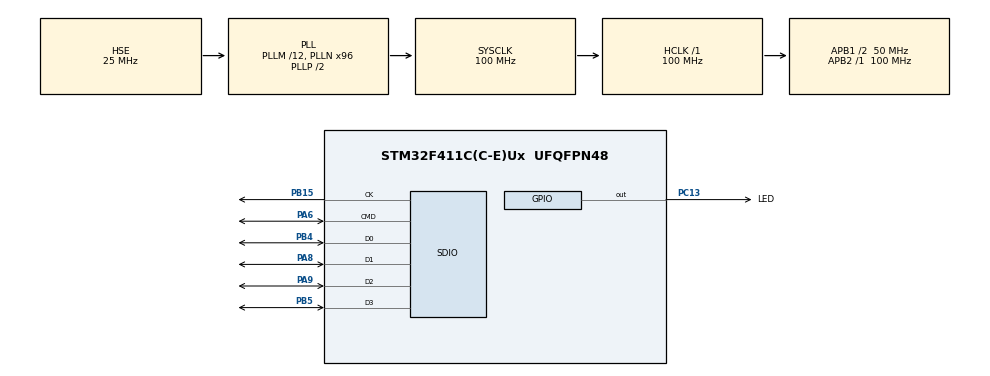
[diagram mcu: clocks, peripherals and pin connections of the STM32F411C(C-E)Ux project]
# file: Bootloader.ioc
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FATFS._MAX_SS=4096
Mcu.Family=STM32F4
Mcu.Name=STM32F411C(C-E)Ux
Mcu.Package=UFQFPN48
NVIC.PriorityGroup=NVIC_PRIORITYGROUP_4
PA13.Mode=Trace_Asynchronous_SW
PA13.Signal=SYS_JTMS-SWDIO
PA14.Mode=Trace_Asynchronous_SW
PA14.Signal=SYS_JTCK-SWCLK
PA6.GPIO_PuPd=GPIO_PULLUP
PA6.Mode=SD_4_bits_Wide_bus
PA6.Signal=SDIO_CMD
PA8.GPIO_PuPd=GPIO_PULLUP
PA8.Mode=SD_4_bits_Wide_bus
PA8.Signal=SDIO_D1
PA9.GPIO_PuPd=GPIO_PULLUP
PA9.Mode=SD_4_bits_Wide_bus
PA9.Signal=SDIO_D2
PB15.GPIO_PuPd=GPIO_NOPULL
PB15.Mode=SD_4_bits_Wide_bus
PB15.Signal=SDIO_CK
PB3.Mode=Trace_Asynchronous_SW
PB3.Signal=SYS_JTDO-SWO
PB4.GPIO_PuPd=GPIO_PULLUP
PB4.Mode=SD_4_bits_Wide_bus
PB4.Signal=SDIO_D0
PB5.GPIO_PuPd=GPIO_PULLUP
PB5.Mode=SD_4_bits_Wide_bus
PB5.Signal=SDIO_D3
PC13-ANTI_TAMP.GPIO_Label=LED
PC13-ANTI_TAMP.PinState=GPIO_PIN_SET
PC13-ANTI_TAMP.Signal=GPIO_Output
PH0\ -\ OSC_IN.Mode=HSE-External-Oscillator
PH0\ -\ OSC_IN.Signal=RCC_OSC_IN
PH1\ -\ OSC_OUT.Mode=HSE-External-Oscillator
PH1\ -\ OSC_OUT.Signal=RCC_OSC_OUT
ProjectManager.HeapSize=0x200
ProjectManager.StackSize=0x400
ProjectManager.TargetToolchain=STM32CubeIDE
RCC.48MHZClocksFreq_Value=40000000
RCC.AHBFreq_Value=100000000
RCC.APB1CLKDivider=RCC_HCLK_DIV2
RCC.APB1Freq_Value=50000000
RCC.APB1TimFreq_Value=100000000
RCC.APB2Freq_Value=100000000
RCC.APB2TimFreq_Value=100000000
RCC.CortexFreq_Value=100000000
RCC.HCLKFreq_Value=100000000
RCC.HSE_VALUE=25000000
RCC.HSI_VALUE=16000000
RCC.LSE_VALUE=32768
RCC.PLLM=12
RCC.PLLN=96
RCC.PLLQ=5
RCC.PLLSourceVirtual=RCC_PLLSOURCE_HSE
RCC.SYSCLKFreq_VALUE=100000000
RCC.SYSCLKSource=RCC_SYSCLKSOURCE_PLLCLK
RCC.VCOOutputFreq_Value=200000000
SDIO.ClockDiv=10
VP_FATFS_VS_SDIO.Mode=SDIO
board=custom

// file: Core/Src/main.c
/* USER CODE BEGIN Header */
/**
  ******************************************************************************
  * @file           : main.c
  * @brief          : Main program body
  ******************************************************************************
  * @attention
  *
  * <h2><center>&copy; Copyright (c) 2023 STMicroelectronics.
  * All rights reserved.</center></h2>
  *
  * This software component is licensed by ST under BSD 3-Clause license,
  * the "License"; You may not use this file except in compliance with the
  * License. You may obtain a copy of the License at:
  *                        opensource.org/licenses/BSD-3-Clause
  *
  ******************************************************************************
  */
/* USER CODE END Header */
#include "main.h"
#include "fatfs.h"

SD_HandleTypeDef hsd;

void SystemClock_Config(void);
static void MX_GPIO_Init(void);
static void MX_SDIO_SD_Init(void);

int main(void)
{

  /* MCU Configuration--------------------------------------------------------*/

  /* Reset of all peripherals, Initializes the Flash interface and the Systick. */
  HAL_Init();

  /* Configure the system clock */
  SystemClock_Config();

  /* Initialize all configured peripherals */
  MX_GPIO_Init();
  MX_SDIO_SD_Init();
  MX_FATFS_Init();
  /* USER CODE BEGIN 2 */

	for (uint8_t i = 0; i < 4; i++) {		// тестовое моргание диодом
		HAL_GPIO_TogglePin(LED_GPIO_Port, LED_Pin);
		HAL_Delay(500);
	}

	Bootloader_Main();

  /* USER CODE END 2 */

  /* Infinite loop */
  while (1)
  {

  }
}

void SystemClock_Config(void)
{
  RCC_OscInitTypeDef RCC_OscInitStruct = {0};
  RCC_ClkInitTypeDef RCC_ClkInitStruct = {0};

  /** Configure the main internal regulator output voltage
  */
  __HAL_RCC_PWR_CLK_ENABLE();
  __HAL_PWR_VOLTAGESCALING_CONFIG(PWR_REGULATOR_VOLTAGE_SCALE1);
  /** Initializes the RCC Oscillators according to the specified parameters
  * in the RCC_OscInitTypeDef structure.
  */
  RCC_OscInitStruct.OscillatorType = RCC_OSCILLATORTYPE_HSE;
  RCC_OscInitStruct.HSEState = RCC_HSE_ON;
  RCC_OscInitStruct.PLL.PLLState = RCC_PLL_ON;
  RCC_OscInitStruct.PLL.PLLSource = RCC_PLLSOURCE_HSE;
  RCC_OscInitStruct.PLL.PLLM = 12;
  RCC_OscInitStruct.PLL.PLLN = 96;
  RCC_OscInitStruct.PLL.PLLP = RCC_PLLP_DIV2;
  RCC_OscInitStruct.PLL.PLLQ = 5;
  if (HAL_RCC_OscConfig(&RCC_OscInitStruct) != HAL_OK)
  {
    Error_Handler();
  }
  /** Initializes the CPU, AHB and APB buses clocks
  */
  RCC_ClkInitStruct.ClockType = RCC_CLOCKTYPE_HCLK|RCC_CLOCKTYPE_SYSCLK
                              |RCC_CLOCKTYPE_PCLK1|RCC_CLOCKTYPE_PCLK2;
  RCC_ClkInitStruct.SYSCLKSource = RCC_SYSCLKSOURCE_PLLCLK;
  RCC_ClkInitStruct.AHBCLKDivider = RCC_SYSCLK_DIV1;
  RCC_ClkInitStruct.APB1CLKDivider = RCC_HCLK_DIV2;
  RCC_ClkInitStruct.APB2CLKDivider = RCC_HCLK_DIV1;

  if (HAL_RCC_ClockConfig(&RCC_ClkInitStruct, FLASH_LATENCY_3) != HAL_OK)
  {
    Error_Handler();
  }
}

static void MX_SDIO_SD_Init(void)
{

  hsd.Instance = SDIO;
  hsd.Init.ClockEdge = SDIO_CLOCK_EDGE_RISING;
  hsd.Init.ClockBypass = SDIO_CLOCK_BYPASS_DISABLE;
  hsd.Init.ClockPowerSave = SDIO_CLOCK_POWER_SAVE_DISABLE;
  hsd.Init.BusWide = SDIO_BUS_WIDE_1B;
  hsd.Init.HardwareFlowControl = SDIO_HARDWARE_FLOW_CONTROL_DISABLE;
  hsd.Init.ClockDiv = 10;

}

static void MX_GPIO_Init(void)
{
  GPIO_InitTypeDef GPIO_InitStruct = {0};

  /* GPIO Ports Clock Enable */
  __HAL_RCC_GPIOC_CLK_ENABLE();
  __HAL_RCC_GPIOH_CLK_ENABLE();
  __HAL_RCC_GPIOA_CLK_ENABLE();
  __HAL_RCC_GPIOB_CLK_ENABLE();

  /*Configure GPIO pin Output Level */
  HAL_GPIO_WritePin(LED_GPIO_Port, LED_Pin, GPIO_PIN_SET);

  /*Configure GPIO pin : LED_Pin */
  GPIO_InitStruct.Pin = LED_Pin;
  GPIO_InitStruct.Mode = GPIO_MODE_OUTPUT_PP;
  GPIO_InitStruct.Pull = GPIO_NOPULL;
  GPIO_InitStruct.Speed = GPIO_SPEED_FREQ_LOW;
  HAL_GPIO_Init(LED_GPIO_Port, &GPIO_InitStruct);

}

/* USER CODE BEGIN 4 */
int __io_putchar(int ch)
{
	ITM_SendChar(ch);
	return ch;
}
/* USER CODE END 4 */

void Error_Handler(void)
{
  __disable_irq();
  while (1)
  {
  }
}

/************************ (C) COPYRIGHT STMicroelectronics *****END OF FILE****/
